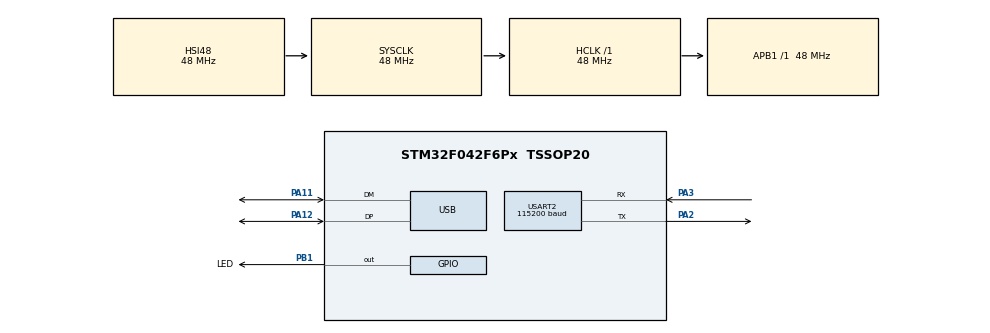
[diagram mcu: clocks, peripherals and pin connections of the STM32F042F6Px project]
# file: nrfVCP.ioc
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Dma.Request0=USART2_TX
Dma.USART2_TX.0.Direction=DMA_MEMORY_TO_PERIPH
Dma.USART2_TX.0.Instance=DMA1_Channel4
Dma.USART2_TX.0.MemDataAlignment=DMA_MDATAALIGN_BYTE
Dma.USART2_TX.0.MemInc=DMA_MINC_ENABLE
Dma.USART2_TX.0.Mode=DMA_NORMAL
Dma.USART2_TX.0.PeriphDataAlignment=DMA_PDATAALIGN_BYTE
Dma.USART2_TX.0.PeriphInc=DMA_PINC_DISABLE
Dma.USART2_TX.0.Priority=DMA_PRIORITY_LOW
Mcu.Family=STM32F0
Mcu.Name=STM32F042F6Px
Mcu.Package=TSSOP20
NVIC.DMA1_Channel4_5_IRQn=true\:0\:0\:false\:false\:true\:false
NVIC.TIM3_IRQn=true\:0\:0\:false\:false\:true\:true
NVIC.USART2_IRQn=true\:0\:0\:false\:false\:true\:true
NVIC.USB_IRQn=true\:0\:0\:false\:false\:true\:false
PA11.Mode=Device
PA11.Signal=USB_DM
PA12.Mode=Device
PA12.Signal=USB_DP
PA13.Mode=Serial_Wire
PA13.Signal=SYS_SWDIO
PA14.Mode=Serial_Wire
PA14.Signal=SYS_SWCLK
PA2.Mode=Asynchronous
PA2.Signal=USART2_TX
PA3.Mode=Asynchronous
PA3.Signal=USART2_RX
PB1.GPIO_Label=LED
PB1.GPIO_PuPd=GPIO_NOPULL
PB1.Signal=GPIO_Output
ProjectManager.HeapSize=0x200
ProjectManager.StackSize=0x400
ProjectManager.TargetToolchain=MDK-ARM V5
RCC.AHBFreq_Value=48000000
RCC.APB1Freq_Value=48000000
RCC.APB1TimFreq_Value=48000000
RCC.HCLKFreq_Value=48000000
RCC.SYSCLKFreq_VALUE=48000000
RCC.SYSCLKSource=RCC_SYSCLKSOURCE_HSI48
TIM3.AutoReloadPreload=TIM_AUTORELOAD_PRELOAD_ENABLE
TIM3.Period=999
TIM3.Prescaler=47
USART2.BaudRate=115200
USART2.VirtualMode-Asynchronous=VM_ASYNC
USB_DEVICE.CLASS_NAME_FS=CDC
USB_DEVICE.VirtualMode=Cdc
USB_DEVICE.VirtualModeFS=Cdc_FS
VP_SYS_VS_PINREMAP.Mode=PINREMAP
VP_TIM3_VS_ClockSourceINT.Mode=Internal
VP_USB_DEVICE_VS_USB_DEVICE_CDC_FS.Mode=CDC_FS
board=custom

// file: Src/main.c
/**
  ******************************************************************************
  * @file           : main.c
  * @brief          : Main program body
  ******************************************************************************
  * This notice applies to any and all portions of this file
  * that are not between comment pairs USER CODE BEGIN and
  * USER CODE END. Other portions of this file, whether
  * inserted by the user or by software development tools
  * are owned by their respective copyright owners.
  *
  * Copyright (c) 2019 STMicroelectronics International N.V.
  * All rights reserved.
  *
  * Redistribution and use in source and binary forms, with or without
  * modification, are permitted, provided that the following conditions are met:
  *
  * 1. Redistribution of source code must retain the above copyright notice,
  *    this list of conditions and the following disclaimer.
  * 2. Redistributions in binary form must reproduce the above copyright notice,
  *    this list of conditions and the following disclaimer in the documentation
  *    and/or other materials provided with the distribution.
  * 3. Neither the name of STMicroelectronics nor the names of other
  *    contributors to this software may be used to endorse or promote products
  *    derived from this software without specific written permission.
  * 4. This software, including modifications and/or derivative works of this
  *    software, must execute solely and exclusively on microcontroller or
  *    microprocessor devices manufactured by or for STMicroelectronics.
  * 5. Redistribution and use of this software other than as permitted under
  *    this license is void and will automatically terminate your rights under
  *    this license.
  *
  * THIS SOFTWARE IS PROVIDED BY STMICROELECTRONICS AND CONTRIBUTORS "AS IS"
  * AND ANY EXPRESS, IMPLIED OR STATUTORY WARRANTIES, INCLUDING, BUT NOT
  * LIMITED TO, THE IMPLIED WARRANTIES OF MERCHANTABILITY, FITNESS FOR A
  * PARTICULAR PURPOSE AND NON-INFRINGEMENT OF THIRD PARTY INTELLECTUAL PROPERTY
  * RIGHTS ARE DISCLAIMED TO THE FULLEST EXTENT PERMITTED BY LAW. IN NO EVENT
  * SHALL STMICROELECTRONICS OR CONTRIBUTORS BE LIABLE FOR ANY DIRECT, INDIRECT,
  * INCIDENTAL, SPECIAL, EXEMPLARY, OR CONSEQUENTIAL DAMAGES (INCLUDING, BUT NOT
  * LIMITED TO, PROCUREMENT OF SUBSTITUTE GOODS OR SERVICES; LOSS OF USE, DATA,
  * OR PROFITS; OR BUSINESS INTERRUPTION) HOWEVER CAUSED AND ON ANY THEORY OF
  * LIABILITY, WHETHER IN CONTRACT, STRICT LIABILITY, OR TORT (INCLUDING
  * NEGLIGENCE OR OTHERWISE) ARISING IN ANY WAY OUT OF THE USE OF THIS SOFTWARE,
  * EVEN IF ADVISED OF THE POSSIBILITY OF SUCH DAMAGE.
  *
  ******************************************************************************
  */
#include "main.h"
#include "stm32f0xx_hal.h"
#include "dma.h"
#include "tim.h"
#include "usart.h"
#include "usb_device.h"
#include "gpio.h"

/* USER CODE BEGIN PV */
/* Private variables ---------------------------------------------------------*/

/* USER CODE END PV */

void SystemClock_Config(void);

/* USER CODE BEGIN PFP */
/* Private function prototypes -----------------------------------------------*/

/* USER CODE END PFP */

int main(void)
{

  /* MCU Configuration----------------------------------------------------------*/

  /* Reset of all peripherals, Initializes the Flash interface and the Systick. */
  HAL_Init();

  /* Configure the system clock */
  SystemClock_Config();

  /* Initialize all configured peripherals */
  MX_GPIO_Init();
  MX_DMA_Init();
  MX_USB_DEVICE_Init();
  MX_USART2_UART_Init();
  MX_TIM3_Init();
  /* USER CODE BEGIN 2 */
  /* Start the TIM Base generation in interrupt mode ####################*/
  if(HAL_TIM_Base_Start_IT(&htim3) != HAL_OK)
  {
    /* Starting Error */
    _Error_Handler(__FILE__, __LINE__);
  }
  /* USER CODE END 2 */

  /* Infinite loop */
  while (1)
  {

  }

}

void SystemClock_Config(void)
{

  RCC_OscInitTypeDef RCC_OscInitStruct;
  RCC_ClkInitTypeDef RCC_ClkInitStruct;
  RCC_PeriphCLKInitTypeDef PeriphClkInit;

    /**Initializes the CPU, AHB and APB busses clocks
    */
  RCC_OscInitStruct.OscillatorType = RCC_OSCILLATORTYPE_HSI48;
  RCC_OscInitStruct.HSI48State = RCC_HSI48_ON;
  RCC_OscInitStruct.PLL.PLLState = RCC_PLL_NONE;
  if (HAL_RCC_OscConfig(&RCC_OscInitStruct) != HAL_OK)
  {
    _Error_Handler(__FILE__, __LINE__);
  }

    /**Initializes the CPU, AHB and APB busses clocks
    */
  RCC_ClkInitStruct.ClockType = RCC_CLOCKTYPE_HCLK|RCC_CLOCKTYPE_SYSCLK
                              |RCC_CLOCKTYPE_PCLK1;
  RCC_ClkInitStruct.SYSCLKSource = RCC_SYSCLKSOURCE_HSI48;
  RCC_ClkInitStruct.AHBCLKDivider = RCC_SYSCLK_DIV1;
  RCC_ClkInitStruct.APB1CLKDivider = RCC_HCLK_DIV1;

  if (HAL_RCC_ClockConfig(&RCC_ClkInitStruct, FLASH_LATENCY_1) != HAL_OK)
  {
    _Error_Handler(__FILE__, __LINE__);
  }

  PeriphClkInit.PeriphClockSelection = RCC_PERIPHCLK_USB;
  PeriphClkInit.UsbClockSelection = RCC_USBCLKSOURCE_HSI48;

  if (HAL_RCCEx_PeriphCLKConfig(&PeriphClkInit) != HAL_OK)
  {
    _Error_Handler(__FILE__, __LINE__);
  }

    /**Configure the Systick interrupt time
    */
  HAL_SYSTICK_Config(HAL_RCC_GetHCLKFreq()/1000);

    /**Configure the Systick
    */
  HAL_SYSTICK_CLKSourceConfig(SYSTICK_CLKSOURCE_HCLK);

  /* SysTick_IRQn interrupt configuration */
  HAL_NVIC_SetPriority(SysTick_IRQn, 0, 0);
}

void _Error_Handler(char *file, int line)
{
  while(1)
  {
  }
}

/************************ (C) COPYRIGHT STMicroelectronics *****END OF FILE****/
